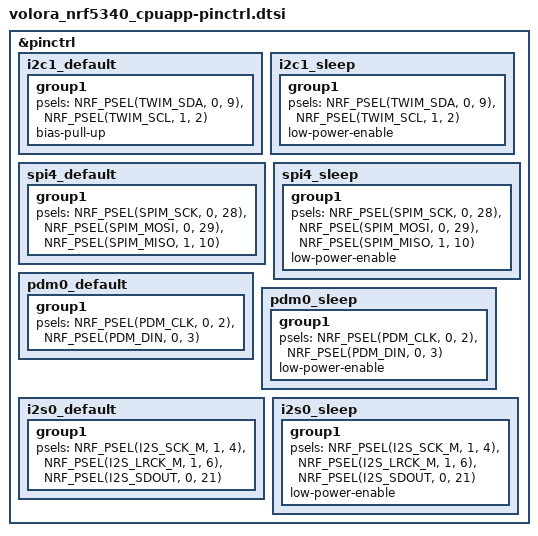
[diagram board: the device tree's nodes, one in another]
&pinctrl {
	i2c1_default: i2c1_default {
		group1 {
			psels = <NRF_PSEL(TWIM_SDA, 0, 9)>,
				<NRF_PSEL(TWIM_SCL, 1, 2)>;
			bias-pull-up;
		};
	};

	i2c1_sleep: i2c1_sleep {
		group1 {
			psels = <NRF_PSEL(TWIM_SDA, 0, 9)>,
				<NRF_PSEL(TWIM_SCL, 1, 2)>;
			low-power-enable;
		};
	};

	spi4_default: spi4_default {
		group1 {
			psels = <NRF_PSEL(SPIM_SCK, 0, 28)>,
				<NRF_PSEL(SPIM_MOSI, 0, 29)>,
				<NRF_PSEL(SPIM_MISO, 1, 10)>;
		};
	};

	spi4_sleep: spi4_sleep {
		group1 {
			psels = <NRF_PSEL(SPIM_SCK, 0, 28)>,
				<NRF_PSEL(SPIM_MOSI, 0, 29)>,
				<NRF_PSEL(SPIM_MISO, 1, 10)>;
			low-power-enable;
		};
	};

	pdm0_default: pdm0_default {
		group1 {
			psels = <NRF_PSEL(PDM_CLK, 0, 2)>,
				<NRF_PSEL(PDM_DIN, 0, 3)>;
		};
	};

	pdm0_sleep: pdm0_sleep {
		group1 {
			psels = <NRF_PSEL(PDM_CLK, 0, 2)>,
				<NRF_PSEL(PDM_DIN, 0, 3)>;
			low-power-enable;
		};
	};

	i2s0_default: i2s0_default {
		group1 {
			psels = <NRF_PSEL(I2S_SCK_M, 1, 4)>,
				<NRF_PSEL(I2S_LRCK_M, 1, 6)>,
				<NRF_PSEL(I2S_SDOUT, 0, 21)>;
		};
	};

	i2s0_sleep: i2s0_sleep {
		group1 {
			psels = <NRF_PSEL(I2S_SCK_M, 1, 4)>,
				<NRF_PSEL(I2S_LRCK_M, 1, 6)>,
				<NRF_PSEL(I2S_SDOUT, 0, 21)>;
			low-power-enable;
		};
	};
};
